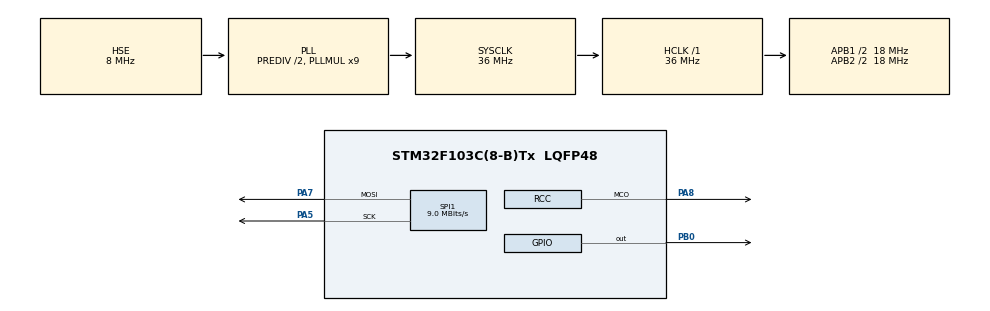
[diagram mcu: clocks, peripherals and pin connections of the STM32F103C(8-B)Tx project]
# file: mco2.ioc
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Mcu.Family=STM32F1
Mcu.Name=STM32F103C(8-B)Tx
Mcu.Package=LQFP48
NVIC.PriorityGroup=NVIC_PRIORITYGROUP_4
PA5.Mode=TX_Only_Simplex_Unidirect_Master
PA5.Signal=SPI1_SCK
PA7.Mode=TX_Only_Simplex_Unidirect_Master
PA7.Signal=SPI1_MOSI
PA8.Mode=Clock-out
PA8.Signal=RCC_MCO
PB0.Signal=GPIO_Output
PD0-OSC_IN.Mode=HSE-External-Oscillator
PD0-OSC_IN.Signal=RCC_OSC_IN
PD1-OSC_OUT.Mode=HSE-External-Oscillator
PD1-OSC_OUT.Signal=RCC_OSC_OUT
ProjectManager.HeapSize=0x200
ProjectManager.StackSize=0x400
ProjectManager.TargetToolchain=MDK-ARM V5
RCC.AHBFreq_Value=36000000
RCC.APB1CLKDivider=RCC_HCLK_DIV2
RCC.APB1Freq_Value=18000000
RCC.APB1TimFreq_Value=36000000
RCC.APB2CLKDivider=RCC_HCLK_DIV2
RCC.APB2Freq_Value=18000000
RCC.APB2TimFreq_Value=36000000
RCC.HCLKFreq_Value=36000000
RCC.HSEDivPLL=RCC_HSE_PREDIV_DIV2
RCC.PLLMUL=RCC_PLL_MUL9
RCC.PLLSourceVirtual=RCC_PLLSOURCE_HSE
RCC.RCC_MCOSource=RCC_MCO1SOURCE_PLLCLK
RCC.SYSCLKFreq_VALUE=36000000
RCC.SYSCLKSource=RCC_SYSCLKSOURCE_PLLCLK
RCC.USBFreq_Value=36000000
SPI1.CalculateBaudRate=9.0 MBits/s
SPI1.DataSize=SPI_DATASIZE_16BIT
SPI1.Direction=SPI_DIRECTION_2LINES
SPI1.Mode=SPI_MODE_MASTER
SPI1.VirtualType=VM_MASTER
VP_SYS_VS_ND.Mode=No_Debug
board=custom

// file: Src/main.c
#include "main.h"
#include "stm32f1xx_hal.h"

SPI_HandleTypeDef hspi1;

/* USER CODE BEGIN PV */
/* Private variables ---------------------------------------------------------*/
uint16_t data_tx = 0x8714;
/* USER CODE END PV */

void SystemClock_Config(void);
static void MX_GPIO_Init(void);
static void MX_SPI1_Init(void);

/* USER CODE BEGIN PFP */
/* Private function prototypes -----------------------------------------------*/

/* USER CODE END PFP */

int main(void)
{

  /* MCU Configuration----------------------------------------------------------*/

  /* Reset of all peripherals, Initializes the Flash interface and the Systick. */
  HAL_Init();

  /* Configure the system clock */
  SystemClock_Config();

  /* Initialize all configured peripherals */
  MX_GPIO_Init();
  MX_SPI1_Init();
  /* USER CODE BEGIN 2 */
		HAL_GPIO_WritePin(GPIOB, GPIO_PIN_0, GPIO_PIN_SET);
		HAL_GPIO_WritePin(GPIOB, GPIO_PIN_0, GPIO_PIN_RESET);
		HAL_Delay(1);
		HAL_SPI_Transmit(&hspi1,(uint8_t*)&data_tx,2,10);
		HAL_Delay(2);
		HAL_GPIO_WritePin(GPIOB, GPIO_PIN_0, GPIO_PIN_SET);
  /* USER CODE END 2 */

  /* Infinite loop */
  while (1)
  {

  }

}

void SystemClock_Config(void)
{

  RCC_OscInitTypeDef RCC_OscInitStruct;
  RCC_ClkInitTypeDef RCC_ClkInitStruct;

    /**Initializes the CPU, AHB and APB busses clocks
    */
  RCC_OscInitStruct.OscillatorType = RCC_OSCILLATORTYPE_HSE;
  RCC_OscInitStruct.HSEState = RCC_HSE_ON;
  RCC_OscInitStruct.HSEPredivValue = RCC_HSE_PREDIV_DIV2;
  RCC_OscInitStruct.HSIState = RCC_HSI_ON;
  RCC_OscInitStruct.PLL.PLLState = RCC_PLL_ON;
  RCC_OscInitStruct.PLL.PLLSource = RCC_PLLSOURCE_HSE;
  RCC_OscInitStruct.PLL.PLLMUL = RCC_PLL_MUL9;
  if (HAL_RCC_OscConfig(&RCC_OscInitStruct) != HAL_OK)
  {
    _Error_Handler(__FILE__, __LINE__);
  }

    /**Initializes the CPU, AHB and APB busses clocks
    */
  RCC_ClkInitStruct.ClockType = RCC_CLOCKTYPE_HCLK|RCC_CLOCKTYPE_SYSCLK
                              |RCC_CLOCKTYPE_PCLK1|RCC_CLOCKTYPE_PCLK2;
  RCC_ClkInitStruct.SYSCLKSource = RCC_SYSCLKSOURCE_PLLCLK;
  RCC_ClkInitStruct.AHBCLKDivider = RCC_SYSCLK_DIV1;
  RCC_ClkInitStruct.APB1CLKDivider = RCC_HCLK_DIV2;
  RCC_ClkInitStruct.APB2CLKDivider = RCC_HCLK_DIV2;

  if (HAL_RCC_ClockConfig(&RCC_ClkInitStruct, FLASH_LATENCY_1) != HAL_OK)
  {
    _Error_Handler(__FILE__, __LINE__);
  }

  HAL_RCC_MCOConfig(RCC_MCO, RCC_MCO1SOURCE_PLLCLK, RCC_MCODIV_1);

    /**Configure the Systick interrupt time
    */
  HAL_SYSTICK_Config(HAL_RCC_GetHCLKFreq()/1000);

    /**Configure the Systick
    */
  HAL_SYSTICK_CLKSourceConfig(SYSTICK_CLKSOURCE_HCLK);

  /* SysTick_IRQn interrupt configuration */
  HAL_NVIC_SetPriority(SysTick_IRQn, 0, 0);
}

/* SPI1 init function */
static void MX_SPI1_Init(void)
{

  /* SPI1 parameter configuration*/
  hspi1.Instance = SPI1;
  hspi1.Init.Mode = SPI_MODE_MASTER;
  hspi1.Init.Direction = SPI_DIRECTION_2LINES;
  hspi1.Init.DataSize = SPI_DATASIZE_16BIT;
  hspi1.Init.CLKPolarity = SPI_POLARITY_LOW;
  hspi1.Init.CLKPhase = SPI_PHASE_1EDGE;
  hspi1.Init.NSS = SPI_NSS_SOFT;
  hspi1.Init.BaudRatePrescaler = SPI_BAUDRATEPRESCALER_2;
  hspi1.Init.FirstBit = SPI_FIRSTBIT_MSB;
  hspi1.Init.TIMode = SPI_TIMODE_DISABLE;
  hspi1.Init.CRCCalculation = SPI_CRCCALCULATION_DISABLE;
  hspi1.Init.CRCPolynomial = 10;
  if (HAL_SPI_Init(&hspi1) != HAL_OK)
  {
    _Error_Handler(__FILE__, __LINE__);
  }

}

/** Configure pins as
        * Analog
        * Input
        * Output
        * EVENT_OUT
        * EXTI
     PA8   ------> RCC_MCO
*/
static void MX_GPIO_Init(void)
{

  GPIO_InitTypeDef GPIO_InitStruct;

  /* GPIO Ports Clock Enable */
  __HAL_RCC_GPIOD_CLK_ENABLE();
  __HAL_RCC_GPIOA_CLK_ENABLE();
  __HAL_RCC_GPIOB_CLK_ENABLE();

  /*Configure GPIO pin Output Level */
  HAL_GPIO_WritePin(GPIOB, GPIO_PIN_0, GPIO_PIN_RESET);

  /*Configure GPIO pin : PB0 */
  GPIO_InitStruct.Pin = GPIO_PIN_0;
  GPIO_InitStruct.Mode = GPIO_MODE_OUTPUT_PP;
  GPIO_InitStruct.Pull = GPIO_NOPULL;
  GPIO_InitStruct.Speed = GPIO_SPEED_FREQ_LOW;
  HAL_GPIO_Init(GPIOB, &GPIO_InitStruct);

  /*Configure GPIO pin : PA8 */
  GPIO_InitStruct.Pin = GPIO_PIN_8;
  GPIO_InitStruct.Mode = GPIO_MODE_AF_PP;
  GPIO_InitStruct.Speed = GPIO_SPEED_FREQ_LOW;
  HAL_GPIO_Init(GPIOA, &GPIO_InitStruct);

}

void _Error_Handler(char *file, int line)
{
  while(1)
  {
  }
}
